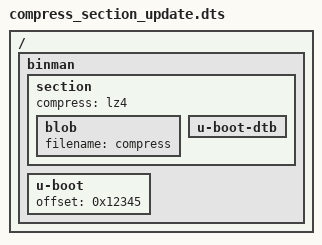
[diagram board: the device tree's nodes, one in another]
// SPDX-License-Identifier: GPL-2.0+
/dts-v1/;

/ {
	binman {
		section {
			compress = "lz4";
			blob {
				filename = "compress";
			};
			u-boot-dtb {
			};
		};
		u-boot {
			offset = <0x12345>;
		};
	};
};
